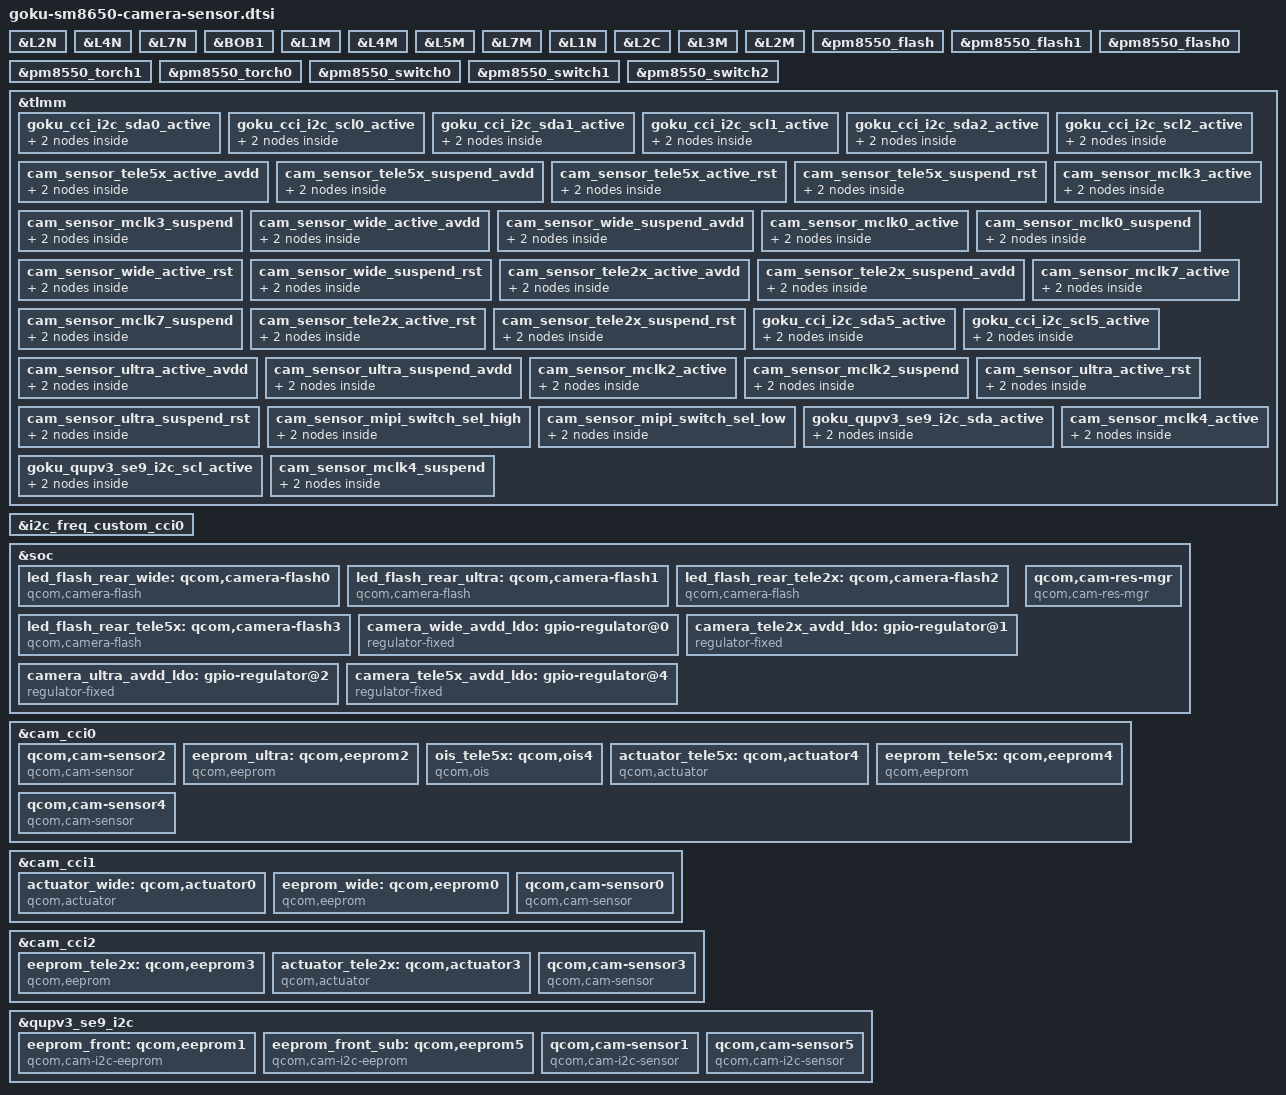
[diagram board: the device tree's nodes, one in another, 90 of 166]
#include <dt-bindings/msm-camera.h>

&L2N {
	regulator-min-microvolt = <1052000>;
	regulator-max-microvolt = <1052000>;
	qcom,init-voltage = <1052000>;
};

&L4N {
	regulator-min-microvolt = <2800000>;
	regulator-max-microvolt = <2800000>;
	qcom,init-voltage = <2800000>;
};

&L7N {
	regulator-min-microvolt = <2840000>;
	regulator-max-microvolt = <2840000>;
	qcom,init-voltage = <2840000>;
};

&BOB1{
	regulator-min-microvolt = <2704000>;
	regulator-max-microvolt = <3584000>;
	qcom,init-voltage = <3296000>;
};

&L1M {
	regulator-min-microvolt = <1160000>;
	regulator-max-microvolt = <1160000>;
	qcom,init-voltage = <1160000>;
};

&L4M {
	regulator-min-microvolt = <3144000>;
	regulator-max-microvolt = <3144000>;
	qcom,init-voltage = <3144000>;
};

&L5M {
	regulator-min-microvolt = <1800000>;
	regulator-max-microvolt = <1800000>;
	qcom,init-voltage = <1800000>;
};
&L7M {
	regulator-min-microvolt = <3112000>;
	regulator-max-microvolt = <3112000>;
	qcom,init-voltage = <3112000>;
};

&L1N {
	regulator-min-microvolt = <1104000>;
	regulator-max-microvolt = <1104000>;
	qcom,init-voltage = <1104000>;
};

&L2C {
	regulator-min-microvolt = <1216000>;
	regulator-max-microvolt = <1216000>;
	qcom,init-voltage = <1216000>;
};


&L3M{
	regulator-min-microvolt = <2824000>;
	regulator-max-microvolt = <2824000>;
	qcom,init-voltage = <2824000>;
};

&L2M {
	regulator-min-microvolt = <1232000>;
	regulator-max-microvolt = <1232000>;
	qcom,init-voltage = <1232000>;
};

&L5M {
	regulator-min-microvolt = <1800000>;
	regulator-max-microvolt = <1800000>;
	qcom,init-voltage = <1800000>;
};

&pm8550_flash {
	status = "ok";
};

&pm8550_flash1 {
	qcom,duration-ms = <300>;
	xiaomi,max-duration-ms = <300>;
	qcom,max-current-ma = <300>;
};

&pm8550_flash0 {
	qcom,duration-ms = <300>;
	xiaomi,max-duration-ms = <300>;
	qcom,max-current-ma = <300>;
};

&pm8550_torch1{
	qcom,max-current-ma = <300>;
	xiaomi,currents-with-time = <300 225>;
	xiaomi,time-for-currents = <5000 0xFFFFFFFF>;
};

&pm8550_torch0{
	qcom,max-current-ma = <300>;
	xiaomi,currents-with-time = <300 225>;
	xiaomi,time-for-currents = <5000 0xFFFFFFFF>;
};

&pm8550_switch0 {
	qcom,led-mask = <1>;
	qcom,symmetry-en;
};

&pm8550_switch1 {
	qcom,led-mask = <2>;
	qcom,symmetry-en;
};

&pm8550_switch2 {
	qcom,led-mask = <3>;
	qcom,symmetry-en;
};

&tlmm {
	goku_cci_i2c_sda0_active: goku_cci_i2c_sda0_active {
		mux {
			/* CLK, DATA */
			pins = "gpio113";
			function = "cci_i2c_sda0";
		};

		config {
			pins = "gpio113";
			bias-disable; /* NO PULL */
			drive-strength = <2>; /* 2 MA */
		};
	};

	goku_cci_i2c_scl0_active: goku_cci_i2c_scl0_active {
		mux {
			/* CLK, DATA */
			pins = "gpio114";
			function = "cci_i2c_scl0";
		};

		config {
			pins = "gpio114";
			bias-disable; /* NO PULL */
			drive-strength = <2>; /* 2 MA */
		};
	};

	goku_cci_i2c_sda1_active: goku_cci_i2c_sda1_active {
		mux {
			/* CLK, DATA */
			pins = "gpio115";
			function = "cci_i2c_sda1";
		};

		config {
			pins = "gpio115";
			bias-disable; /* NO PULL */
			drive-strength = <2>; /* 2 MA */
		};
	};

	goku_cci_i2c_scl1_active: goku_cci_i2c_scl1_active {
		mux {
			/* CLK, DATA */
			pins = "gpio116";
			function = "cci_i2c_scl1";
		};

		config {
			pins = "gpio116";
			bias-disable; /* NO PULL */
			drive-strength = <2>; /* 2 MA */
		};
	};

	goku_cci_i2c_sda2_active: goku_cci_i2c_sda2_active {
		mux {
			/* CLK, DATA */
			pins = "gpio117";
			function = "cci_i2c_sda2";
		};

		config {
			pins = "gpio117";
			bias-disable; /* NO PULL */
			drive-strength = <2>; /* 2 MA */
		};
	};

	goku_cci_i2c_scl2_active: goku_cci_i2c_scl2_active {
		mux {
			/* CLK, DATA */
			pins = "gpio118";
			function = "cci_i2c_scl2";
		};

		config {
			pins = "gpio118";
			bias-disable; /* NO PULL */
			drive-strength = <2>; /* 2 MA */
		};
	};

	// TELE5X
	cam_sensor_tele5x_active_avdd: cam_sensor_tele5x_active_avdd {
		mux {
			pins = "gpio82";
			function = "gpio";
		};

		config {
			pins = "gpio82";
			bias-disable; /* No PULL */
			drive-strength = <2>; /* 2 MA */
		};
	};

	cam_sensor_tele5x_suspend_avdd: cam_sensor_tele5x_suspend_avdd {
		mux {
			pins = "gpio82";
			function = "gpio";
		};

		config {
			pins = "gpio82";
			bias-disable; /* No PULL */
			drive-strength = <2>; /* 2 MA */
		};
	};

	cam_sensor_tele5x_active_rst: cam_sensor_tele5x_active_rst {
		mux {
			pins = "gpio110";
			function = "gpio";
		};

		config {
			pins = "gpio110";
			bias-disable; /* No PULL */
			drive-strength = <2>; /* 2 MA */
		};
	};

	cam_sensor_tele5x_suspend_rst: cam_sensor_tele5x_suspend_rst {
		mux {
			pins = "gpio110";
			function = "gpio";
		};

		config {
			pins = "gpio110";
			bias-pull-down; /* PULL DOWN */
			drive-strength = <2>; /* 2 MA */
			output-low;
		};
	};

	cam_sensor_mclk3_active: cam_sensor_mclk3_active {
		/* MCLK3 */
		mux {
			pins = "gpio103";
			function = "cam_mclk";
		};

		config {
			pins = "gpio103";
			bias-disable; /* No PULL */
			drive-strength = <4>; /* 4 MA */
		};
	};

	cam_sensor_mclk3_suspend: cam_sensor_mclk3_suspend {
		/* MCLK3 */
		mux {
			pins = "gpio103";
			function = "cam_mclk";
		};

		config {
			pins = "gpio103";
			bias-pull-down; /* PULL DOWN */
			drive-strength = <4>; /* 4 MA */
		};
	};


	cam_sensor_wide_active_avdd: cam_sensor_wide_active_avdd {
		mux {
			pins = "gpio178";
			function = "gpio";
		};

		config {
			pins = "gpio178";
			bias-disable; /* No PULL */
			drive-strength = <2>; /* 2 MA */
		};
	};

	cam_sensor_wide_suspend_avdd: cam_sensor_wide_suspend_avdd {
		mux {
			pins = "gpio178";
			function = "gpio";
		};

		config {
			pins = "gpio178";
			bias-pull-down; /* PULL DOWN */
			drive-strength = <2>; /* 2 MA */
			output-low;
		};
	};

	cam_sensor_mclk0_active: cam_sensor_mclk0_active {
		/* MCLK0 */
		mux {
			pins = "gpio100";
			function = "cam_mclk";
		};

		config {
			pins = "gpio100";
			bias-disable; /* No PULL */
			drive-strength = <4>; /* 4 MA */
		};
	};

	cam_sensor_mclk0_suspend: cam_sensor_mclk0_suspend {
		/* MCLK0 */
		mux {
			pins = "gpio100";
			function = "cam_mclk";
		};

		config {
			pins = "gpio100";
			bias-pull-down; /* PULL DOWN */
			drive-strength = <4>; /* 4 MA */
		};
	};

	cam_sensor_wide_active_rst: cam_sensor_wide_active_rst {
		mux {
			pins = "gpio108";
			function = "gpio";
		};

		config {
			pins = "gpio108";
			bias-disable; /* No PULL */
			drive-strength = <2>; /* 2 MA */
		};
	};

	cam_sensor_wide_suspend_rst: cam_sensor_wide_suspend_rst {
		mux {
			pins = "gpio108";
			function = "gpio";
		};

		config {
			pins = "gpio108";
			bias-pull-down; /* PULL DOWN */
			drive-strength = <2>; /* 2 MA */
			output-low;
		};
	};

	// TELE2X
	cam_sensor_tele2x_active_avdd: cam_sensor_tele2x_active_avdd {
		mux {
			pins = "gpio98";
			function = "gpio";
		};

		config {
			pins = "gpio98";
			bias-disable; /* No PULL */
			drive-strength = <2>; /* 2 MA */
		};
	};

	cam_sensor_tele2x_suspend_avdd: cam_sensor_tele2x_suspend_avdd {
		mux {
			pins = "gpio98";
			function = "gpio";
		};

		config {
			pins = "gpio98";
			bias-pull-down; /* PULL DOWN */
			drive-strength = <2>; /* 2 MA */
			output-low;
		};
	};

	cam_sensor_mclk7_active: cam_sensor_mclk7_active {
		/* MCLK7 */
		mux {
			pins = "gpio106";
			function = "cam_mclk";
		};

		config {
			pins = "gpio106";
			bias-disable; /* No PULL */
			drive-strength = <4>; /* 4 MA */
		};
	};

	cam_sensor_mclk7_suspend: cam_sensor_mclk7_suspend {
		/* MCLK7 */
		mux {
			pins = "gpio106";
			function = "cam_mclk";
		};

		config {
			pins = "gpio106";
			bias-pull-down; /* PULL DOWN */
			drive-strength = <4>; /* 4 MA */
		};
	};

	cam_sensor_tele2x_active_rst: cam_sensor_tele2x_active_rst {
		mux {
			pins = "gpio111";
			function = "gpio";
		};

		config {
			pins = "gpio111";
			bias-disable; /* No PULL */
			drive-strength = <2>; /* 2 MA */
		};
	};

	cam_sensor_tele2x_suspend_rst: cam_sensor_tele2x_suspend_rst {
		mux {
			pins = "gpio111";
			function = "gpio";
		};

		config {
			pins = "gpio111";
			bias-pull-down; /* PULL DOWN */
			drive-strength = <2>; /* 2 MA */
			output-low;
		};
	};

	goku_cci_i2c_sda5_active: goku_cci_i2c_sda5_active {
		mux {
			/* CLK, DATA */
			pins = "gpio119";
			function = "cci_i2c_sda5";
		};

		config {
			pins = "gpio119";
			bias-disable; /* NO PULL */
			drive-strength = <2>; /* 2 MA */
		};
	};

	goku_cci_i2c_scl5_active: goku_cci_i2c_scl5_active {
		mux {
			/* CLK, DATA */
			pins = "gpio120";
			function = "cci_i2c_scl5";
		};

		config {
			pins = "gpio120";
			bias-disable; /* NO PULL */
			drive-strength = <2>; /* 2 MA */
		};
	};

	// ULTRA avdd
	cam_sensor_ultra_active_avdd: cam_sensor_ultra_active_avdd {
		mux {
			pins = "gpio99";
			function = "gpio";
		};
		config {
			pins = "gpio99";
			bias-disable; /* No PULL */
			drive-strength = <2>; /* 2 MA */
		};
	};

	cam_sensor_ultra_suspend_avdd: cam_sensor_ultra_suspend_avdd {
		mux {
			pins = "gpio99";
			function = "gpio";
		};
		config {
			pins = "gpio99";
			bias-pull-down; /* PULL DOWN */
			drive-strength = <2>; /* 2 MA */
			output-low;
		};
	};

	//Ultra mclk
	cam_sensor_mclk2_active: cam_sensor_mclk2_active {
		/* MCLK1 */
		mux {
			pins = "gpio101";
			function = "cam_mclk";
		};
		config {
			pins = "gpio101";
			bias-disable; /* No PULL */
			drive-strength = <4>; /* 4 MA */
		};
	};

	cam_sensor_mclk2_suspend: cam_sensor_mclk2_suspend {
		/* MCLK1 */
		mux {
			pins = "gpio101";
			function = "cam_mclk";
		};
		config {
			pins = "gpio101";
			bias-pull-down; /* PULL DOWN */
			drive-strength = <4>; /* 4 MA */
		};
	};

	//Ultra RSN
	cam_sensor_ultra_active_rst: cam_sensor_ultra_active_rst {
		mux {
			pins = "gpio109";
			function = "gpio";
		};
		config {
			pins = "gpio109";
			bias-disable; /* No PULL */
			drive-strength = <2>; /* 2 MA */
		};
	};

	cam_sensor_ultra_suspend_rst: cam_sensor_ultra_suspend_rst {
		mux {
			pins = "gpio109";
			function = "gpio";
		};
		config {
			pins = "gpio109";
			bias-pull-down; /* PULL DOWN */
			drive-strength = <2>; /* 2 MA */
			output-low;
		};
	};

//FRONT


	cam_sensor_mipi_switch_sel_high: cam_sensor_mipi_switch_sel_high {
		/* MIPI SEL HIGH: FRONT SUB ACTIVE */

		mux {
			pins = "gpio91";
			function = "gpio";
		};

		config {
			pins = "gpio91";
			bias-disable; /* No PULL */
			drive-strength = <16>; /* 16 MA */
		};
	};

	cam_sensor_mipi_switch_sel_low: cam_sensor_mipi_switch_sel_low {
		/* MIPI SEL LOW: FRONT MAIN ACTIVE */
		mux {
			pins = "gpio91";
			function = "gpio";
		};

		config {
			pins = "gpio91";
			bias-pull-down; /* PULL DOWN */
			drive-strength = <16>; /* 16 MA */
			output-low;
		};
	};



	goku_qupv3_se9_i2c_sda_active: goku_qupv3_se9_i2c_sda_active {
		mux {
			pins = "gpio4";
			function = "qup2_se1_l0";
		};

		config {
			pins = "gpio4";
			drive-strength = <2>;
			bias-disable; /* NO PULL */
			qcom,apps;
		};
	};

	goku_qupv3_se9_i2c_scl_active: goku_qupv3_se9_i2c_scl_active {
		mux {
			pins = "gpio5";
			function = "qup2_se1_l1";
		};

		config {
			pins = "gpio5";
			drive-strength = <2>;
			bias-disable; /* NO PULL */
			qcom,apps;
		};
	};


	cam_sensor_mclk4_active: cam_sensor_mclk4_active {
		/* MCLK4 */
		mux {
			pins = "gpio104";
			function = "cam_aon_mclk4";
		};

		config {
			pins = "gpio104";
			bias-disable; /* No PULL */
			drive-strength = <4>; /* 4 MA */
		};
	};

	cam_sensor_mclk4_suspend: cam_sensor_mclk4_suspend {
		/* MCLK4 */
		mux {
			pins = "gpio104";
			function = "cam_aon_mclk4";
		};

		config {
			pins = "gpio104";
			bias-pull-down; /* PULL DOWN */
			drive-strength = <4>; /* 4 MA */
		};
	};

};

&i2c_freq_custom_cci0{
	hw-thigh = <16>;
	hw-tlow = <22>;
	hw-tsu-sto = <17>;
	hw-tsu-sta = <18>;
	hw-thd-dat = <16>;
	hw-thd-sta = <15>;
	hw-tbuf = <24>;
	hw-scl-stretch-en = <1>;
	hw-trdhld = <3>;
	hw-tsp = <3>;
	cci-clk-src = <37500000>;
	status = "ok";
};

&soc {
	led_flash_rear_wide: qcom,camera-flash0 {
		cell-index = <0>;
		compatible = "qcom,camera-flash";
		flash-source = <&pm8550_flash0 &pm8550_flash1>;
		torch-source = <&pm8550_torch0 &pm8550_torch1>;
		switch-source = <&pm8550_switch2>;
		status = "ok";
	};

	led_flash_rear_ultra: qcom,camera-flash1 {
		cell-index = <1>;
		compatible = "qcom,camera-flash";
		flash-source = <&pm8550_flash0 &pm8550_flash1>;
		torch-source = <&pm8550_torch0 &pm8550_torch1>;
		switch-source = <&pm8550_switch2>;
		status = "ok";
	};

	led_flash_rear_tele2x: qcom,camera-flash2 {
		cell-index = <2>;
		compatible = "qcom,camera-flash";
		flash-source = <&pm8550_flash0 &pm8550_flash1>;
		torch-source = <&pm8550_torch0 &pm8550_torch1>;
		switch-source = <&pm8550_switch2>;
		status = "ok";
	};

	led_flash_rear_tele5x: qcom,camera-flash3 {
		cell-index = <3>;
		compatible = "qcom,camera-flash";
		flash-source = <&pm8550_flash0 &pm8550_flash1>;
		torch-source = <&pm8550_torch0 &pm8550_torch1>;
		switch-source = <&pm8550_switch2>;
		status = "ok";
	};

	camera_wide_avdd_ldo: gpio-regulator@0 {
		compatible = "regulator-fixed";
		reg = <0x00 0x00>;
		regulator-name = "camera_wide_avdd_ldo";
		regulator-min-microvolt = <2800000>;
		regulator-max-microvolt = <2800000>;
		regulator-enable-ramp-delay = <100>;
		enable-active-high;
		gpio = <&tlmm 178 0>;
		pinctrl-names = "wide_avdd_active", "wide_avdd_suspend";
		pinctrl-0 = <&cam_sensor_wide_active_avdd
					 &cam_sensor_wide_suspend_avdd>;
	};

	camera_tele2x_avdd_ldo: gpio-regulator@1 {
		compatible = "regulator-fixed";
		reg = <0x01 0x00>;
		regulator-name = "camera_tele2x_avdd_ldo";
		regulator-min-microvolt = <2800000>;
		regulator-max-microvolt = <2800000>;
		regulator-enable-ramp-delay = <100>;
		enable-active-high;
		gpio = <&tlmm 98 0>;
		pinctrl-names = "tele2x_avdd_active", "tele2x_avdd_suspend";
		pinctrl-0 = <&cam_sensor_tele2x_active_avdd
					 &cam_sensor_tele2x_suspend_avdd>;
	};

	camera_ultra_avdd_ldo: gpio-regulator@2 {
		compatible = "regulator-fixed";
		reg = <0x02 0x00>;
		regulator-name = "camera_ultra_avdd_ldo";
		regulator-min-microvolt = <2800000>;
		regulator-max-microvolt = <2800000>;
		regulator-enable-ramp-delay = <100>;
		enable-active-high;
		gpio = <&tlmm 99 0>;
		pinctrl-names = "ultra_avdd_active", "ultra_avdd_suspend";
		pinctrl-0 = <&cam_sensor_ultra_active_avdd
					 &cam_sensor_ultra_suspend_avdd>;
	};

	camera_tele5x_avdd_ldo: gpio-regulator@4 {
		compatible = "regulator-fixed";
		reg = <0x04 0x00>;
		regulator-name = "camera_tele5x_avdd_ldo";
		regulator-min-microvolt = <2800000>;
		regulator-max-microvolt = <2800000>;
		regulator-enable-ramp-delay = <100>;
		enable-active-high;
		gpio = <&tlmm 82 0>;
		pinctrl-names = "tele5x_avdd_active", "tele5x_avdd_suspend";
		pinctrl-0 = <&cam_sensor_tele5x_active_avdd
					 &cam_sensor_tele5x_suspend_avdd>;
	};

	qcom,cam-res-mgr {
		compatible = "qcom,cam-res-mgr";
		gpios-shared-pinctrl = <404 411>;
		shared-pctrl-gpio-names = "cam_tele5x", "cam_tele5x";
		pinctrl-names ="cam_tele5x_active", "cam_tele5x_suspend";
		pinctrl-0 = <&cam_sensor_mclk3_active
				&cam_sensor_tele5x_active_rst>;
		pinctrl-1 = <&cam_sensor_mclk3_suspend
				&cam_sensor_tele5x_suspend_rst>;
		status = "ok";
	};
};


&cam_cci0 {
	pinctrl-0 = <&goku_cci_i2c_scl0_active &goku_cci_i2c_sda0_active>;
	pinctrl-2 = <&goku_cci_i2c_scl1_active &goku_cci_i2c_sda1_active>;

	// Ultra Sensor
	qcom,cam-sensor2 {
		cell-index = <2>;
		compatible = "qcom,cam-sensor";
		csiphy-sd-index = <1>;
		eeprom-src = <&eeprom_ultra>;
		led-flash-src = <&led_flash_rear_ultra>;
		sensor-position-roll = <90>;
		sensor-position-pitch = <0>;
		sensor-position-yaw = <180>;
		cam_vana-supply = <&camera_ultra_avdd_ldo>;
		cam_vdig-supply = <&L2C>;
		cam_vio-supply  = <&L5M>;
		cam_clk-supply  = <&cam_cc_titan_top_gdsc>;
		cam_bob2-supply = <&BOB2>;
		regulator-names = "cam_vana", "cam_vio", "cam_vdig",
			"cam_clk", "cam_bob2";
		rgltr-cntrl-support;
		rgltr-min-voltage = <2800000 1800000 1216000 0 2704000>;
		rgltr-max-voltage = <2800000 1800000 1216000 0 3296000>;
		rgltr-load-current = <150000 150000 150000 0 2000000>;
		//use-shared-clk;
		gpio-no-mux = <0>;
		pinctrl-names = "cam_default", "cam_suspend";
		pinctrl-0 = <&cam_sensor_mclk2_active
					&cam_sensor_ultra_active_rst>;
		pinctrl-1 = <&cam_sensor_mclk2_suspend
					&cam_sensor_ultra_suspend_rst>;
		gpios = <&tlmm 101 0>, <&tlmm 109 0>;
		gpio-reset = <1>;
		gpio-req-tbl-num = <0 1>;
		gpio-req-tbl-flags = <1 0>;
		gpio-req-tbl-label = "CAMIF_MCLK1", "CAM_RESET1";
		cci-master = <CCI_MASTER_1>;
		clocks = <&camcc CAM_CC_MCLK1_CLK>;
		clock-names = "cam_clk";
		clock-cntl-level = "nominal";
		clock-rates = <19200000>;
		status = "ok";
	};

	eeprom_ultra: qcom,eeprom2 {
		cell-index = <2>;
		compatible = "qcom,eeprom";
		cam_vana-supply = <&camera_ultra_avdd_ldo>;
		cam_vdig-supply = <&L2C>;
		cam_vio-supply  = <&L5M>;
		cam_clk-supply  = <&cam_cc_titan_top_gdsc>;
		cam_bob2-supply = <&BOB2>;
		regulator-names = "cam_vana", "cam_vio", "cam_vdig",
			"cam_clk", "cam_bob2";
		rgltr-cntrl-support;
		rgltr-min-voltage = <2800000 1800000 1216000 0 2704000>;
		rgltr-max-voltage = <2800000 1800000 1216000 0 3296000>;
		rgltr-load-current = <150000 150000 150000 0 2000000>;
		pinctrl-names = "cam_default", "cam_suspend";
		pinctrl-0 = <&cam_sensor_mclk2_active
					&cam_sensor_ultra_active_rst>;
		pinctrl-1 = <&cam_sensor_mclk2_suspend
					&cam_sensor_ultra_suspend_rst>;
		gpios = <&tlmm 101 0>, <&tlmm 109 0>;
		gpio-reset = <1>;
		gpio-req-tbl-num = <0 1>;
		gpio-req-tbl-flags = <1 0>;
		gpio-req-tbl-label = "CAMIF_MCLK1", "CAM_RESET1";
		cci-master = <CCI_MASTER_1>;
		clocks = <&camcc CAM_CC_MCLK1_CLK>;
		clock-names = "cam_clk";
		clock-cntl-level = "nominal";
		clock-rates = <19200000>;
		status = "ok";
	};


	// Tele5x OIS
	ois_tele5x: qcom,ois4 {
		cell-index = <4>;
		compatible = "qcom,ois";
		cam_vana-supply = <&camera_tele5x_avdd_ldo>;
		cam_vio-supply = <&L5M>;
		cam_vdig-supply = <&L2N>;
		cam_clk-supply = <&cam_cc_titan_top_gdsc>;
		cam_bob2-supply = <&BOB2>;
		cam_bob-supply = <&BOB1>;
		cam_v_custom1-supply = <&L4N>;/*OIS AVDD*/
		cam_vaf-supply = <&L7N>;
		regulator-names = "cam_vana", "cam_vio", "cam_vdig",
			"cam_clk", "cam_bob2", "cam_bob", "cam_v_custom1", "cam_vaf";
		rgltr-cntrl-support;
		rgltr-min-voltage = <2800000 1800000 1052000 0 2704000 2704000 2800000 2840000>;
		rgltr-max-voltage = <2800000 1800000 1052000 0 3296000 3584000 2800000 2840000>;
		rgltr-load-current = <150000 150000 150000 0 2000000 2000000 103000 103000>;
		gpio-no-mux = <0>;
		use-shared-clk;
		gpios = <&tlmm 103 0>, <&tlmm 110 0>;
		gpio-reset = <1>;
		gpio-req-tbl-num = <0 1>;
		gpio-req-tbl-flags = <1 0>;
		gpio-req-tbl-label = "CAMIF_MCLK3", "CAM_RESET_TELE5X";
		cci-master = <CCI_MASTER_0>;
		clocks = <&camcc CAM_CC_MCLK3_CLK>;
		clock-names = "cam_clk";
		clock-cntl-level = "nominal";
		clock-rates = <19200000>;
		status = "ok";
	};

	// Tele5x Actuator
	actuator_tele5x: qcom,actuator4 {
		cell-index = <4>;
		compatible = "qcom,actuator";
		cci-master = <CCI_MASTER_0>;
		cam_vaf-supply = <&L7N>;
		cam_vio-supply = <&L5M>;
		cam_v_custom1-supply = <&L4N>;
		cam_bob-supply = <&BOB1>;
		regulator-names = "cam_vaf", "cam_vio", "cam_v_custom1", "cam_bob";
		rgltr-cntrl-support;
		rgltr-min-voltage = <2840000 1800000 2800000 2704000>;
		rgltr-max-voltage = <2840000 1800000 2800000 3584000>;
		rgltr-load-current = <103000 150000 103000 2000000>;
	};

	eeprom_tele5x: qcom,eeprom4 {
		cell-index = <4>;
		compatible = "qcom,eeprom";
		cam_vana-supply = <&camera_tele5x_avdd_ldo>;
		cam_vio-supply = <&L5M>;
		cam_vdig-supply = <&L2N>;
		cam_clk-supply = <&cam_cc_titan_top_gdsc>;
		cam_bob2-supply = <&BOB2>;
		cam_bob-supply = <&BOB1>;
		cam_v_custom1-supply = <&L4N>;/*OIS AVDD*/
		cam_vaf-supply = <&L7N>;
		regulator-names = "cam_vana", "cam_vio", "cam_vdig",
			"cam_clk", "cam_bob2", "cam_bob", "cam_v_custom1", "cam_vaf";
		rgltr-cntrl-support;
		rgltr-min-voltage = <2800000 1800000 1052000 0 2704000 2704000 2800000 2840000>;
		rgltr-max-voltage = <2800000 1800000 1052000 0 3296000 3584000 2800000 2840000>;
		rgltr-load-current = <150000 150000 150000 0 2000000 2000000 103000 103000>;
		gpio-no-mux = <0>;
		use-shared-clk;
		gpios = <&tlmm 103 0>, <&tlmm 110 0>;
		gpio-reset = <1>;
		gpio-req-tbl-num = <0 1>;
		gpio-req-tbl-flags = <1 0>;
		gpio-req-tbl-label = "CAMIF_MCLK3", "CAM_RESET_TELE5X";
		cci-master = <CCI_MASTER_0>;
		clocks = <&camcc CAM_CC_MCLK3_CLK>;
		clock-names = "cam_clk";
		clock-cntl-level = "nominal";
		clock-rates = <19200000>;
		status = "ok";
	};

	// Tele5x Sensor
	qcom,cam-sensor4 {
		cell-index = <4>;
		compatible = "qcom,cam-sensor";
		csiphy-sd-index = <5>;
		eeprom-src = <&eeprom_tele5x>;
		ois-src = <&ois_tele5x>;
		actuator-src = <&actuator_tele5x>;
		led-flash-src = <&led_flash_rear_tele5x>;
		sensor-position-roll = <90>;
		sensor-position-pitch = <0>;
		sensor-position-yaw = <180>;
		cam_vana-supply = <&camera_tele5x_avdd_ldo>;
		cam_vio-supply = <&L5M>;
		cam_vdig-supply = <&L2N>;
		cam_clk-supply = <&cam_cc_titan_top_gdsc>;
		cam_bob2-supply = <&BOB2>;
		cam_bob-supply = <&BOB1>;
		cam_vaf-supply = <&L7N>;
		cam_v_custom1-supply = <&L4N>;/*OIS AVDD*/
		regulator-names = "cam_vana", "cam_vio", "cam_vdig",
			"cam_clk", "cam_bob2", "cam_bob", "cam_v_custom1", "cam_vaf";
		rgltr-cntrl-support;
		rgltr-min-voltage = <2800000 1800000 1052000 0 2704000 2704000 2800000 2840000>;
		rgltr-max-voltage = <2800000 1800000 1052000 0 3296000 3584000 2800000 2840000>;
		rgltr-load-current = <150000 150000 150000 0 2000000 2000000 103000 103000>;
		gpio-no-mux = <0>;
		use-shared-clk;
		gpios = <&tlmm 103 0>, <&tlmm 110 0>;
		gpio-reset = <1>;
		gpio-req-tbl-num = <0 1>;
		gpio-req-tbl-flags = <1 0>;
		gpio-req-tbl-label = "CAMIF_MCLK3", "CAM_RESET_TELE5X";
		cci-master = <CCI_MASTER_0>;
		clocks = <&camcc CAM_CC_MCLK3_CLK>;
		clock-names = "cam_clk";
		clock-cntl-level = "nominal";
		clock-rates = <19200000>;
		status = "ok";
	};
};

&cam_cci1 {
	pinctrl-0 = <&goku_cci_i2c_scl2_active &goku_cci_i2c_sda2_active>;

    //WIDE SubDev
    actuator_wide: qcom,actuator0 {
		cell-index = <0>;
		compatible = "qcom,actuator";
		cci-master = <CCI_MASTER_0>;
		// cam_bob-supply = <&BOB1>;
		cam_vaf-supply = <&L4M>;
		cam_vio-supply = <&L5M>;
		regulator-names = "cam_vaf", "cam_vio";
		rgltr-cntrl-support;
		rgltr-min-voltage = <3144000 1800000>;
		rgltr-max-voltage = <3144000 1800000>;
		rgltr-load-current = <103000 20000>;
	};

	eeprom_wide: qcom,eeprom0 {
		cell-index = <0>;
		compatible = "qcom,eeprom";
		cam_vana-supply = <&camera_wide_avdd_ldo>;
		cam_vio-supply = <&L5M>;
		cam_vdig-supply = <&L1M>;
		cam_clk-supply = <&cam_cc_titan_top_gdsc>;
		cam_bob2-supply = <&BOB2>;
		cam_bob-supply = <&BOB1>;
		regulator-names = "cam_vana", "cam_vio", "cam_vdig",
			"cam_clk", "cam_bob2", "cam_bob";
		rgltr-cntrl-support;
		rgltr-min-voltage = <2800000 1800000 1160000 0 2704000 2704000>;
		rgltr-max-voltage = <2800000 1800000 1160000 0 3296000 3584000>;
		rgltr-load-current = <150000 150000 150000 0 2000000 2000000>;

		gpio-no-mux = <0>;
		pinctrl-names = "cam_default", "cam_suspend";
		pinctrl-0 = <&cam_sensor_mclk0_active
			&cam_sensor_wide_active_rst>;
		pinctrl-1 = <&cam_sensor_mclk0_suspend
			&cam_sensor_wide_suspend_rst>;
		//use-shared-clk;
		gpios = <&tlmm 100 0>, <&tlmm 108 0>;
		gpio-reset = <1>;
		gpio-req-tbl-num = <0 1>;
		gpio-req-tbl-flags = <1 0>;
		gpio-req-tbl-label = "CAMIF_MCLK0", "CAM_RESET_WIDE";
		cci-master = <CCI_MASTER_0>;
		clocks = <&camcc CAM_CC_MCLK0_CLK>;
		clock-names = "cam_clk";
		clock-cntl-level = "nominal";
		clock-rates = <19200000>;
		status = "ok";
	};

	// Wide Sensor
	qcom,cam-sensor0 {
		cell-index = <0>;
		compatible = "qcom,cam-sensor";
		csiphy-sd-index = <2>;
		led-flash-src = <&led_flash_rear_wide>;
		eeprom-src = <&eeprom_wide>;
		actuator-src = <&actuator_wide>;
		sensor-position-roll = <90>;
		sensor-position-pitch = <0>;
		sensor-position-yaw = <180>;
		cam_vana-supply = <&camera_wide_avdd_ldo>;
		cam_vio-supply = <&L5M>;
		cam_vdig-supply = <&L1M>;
		cam_clk-supply = <&cam_cc_titan_top_gdsc>;
		cam_bob2-supply = <&BOB2>;
		cam_bob-supply = <&BOB1>;
		regulator-names = "cam_vana", "cam_vio", "cam_vdig",
			"cam_clk", "cam_bob2", "cam_bob";
		rgltr-cntrl-support;
		rgltr-min-voltage = <2800000 1800000 1160000 0 2704000 2704000>;
		rgltr-max-voltage = <2800000 1800000 1160000 0 3296000 3584000>;
		rgltr-load-current = <150000 150000 150000 0 2000000 2000000>;
		gpio-no-mux = <0>;
		pinctrl-names = "cam_default", "cam_suspend";
		pinctrl-0 = <&cam_sensor_mclk0_active
			&cam_sensor_wide_active_rst>;
		pinctrl-1 = <&cam_sensor_mclk0_suspend
			&cam_sensor_wide_suspend_rst>;
		//use-shared-clk;
		gpios = <&tlmm 100 0>, <&tlmm 108 0>;
		gpio-reset = <1>;
		gpio-req-tbl-num = <0 1>;
		gpio-req-tbl-flags = <1 0>;
		gpio-req-tbl-label = "CAMIF_MCLK0", "CAM_RESET_WIDE";
		cci-master = <CCI_MASTER_0>;
		clocks = <&camcc CAM_CC_MCLK0_CLK>;
		clock-names = "cam_clk";
		clock-cntl-level = "nominal";
		clock-rates = <19200000>;
		status = "ok";
	};
};

&cam_cci2 {
	pinctrl-2 = <&goku_cci_i2c_sda5_active &goku_cci_i2c_scl5_active>;

	eeprom_tele2x: qcom,eeprom3 {
		cell-index = <3>;
		compatible = "qcom,eeprom";
		cam_vana-supply = <&camera_tele2x_avdd_ldo>;
		cam_vio-supply = <&L5M>;
		cam_vdig-supply = <&L1N>;
		cam_bob2-supply = <&BOB2>;
		cam_bob-supply = <&BOB1>;
		cam_clk-supply = <&cam_cc_titan_top_gdsc>;
		regulator-names = "cam_vana", "cam_vio", "cam_vdig",
					"cam_clk", "cam_bob2", "cam_bob";
		rgltr-cntrl-support;
		rgltr-min-voltage = <2800000 1800000 1104000 0 2704000 2704000>;
		rgltr-max-voltage = <2800000 1800000 1104000 0 3296000 3584000>;
		rgltr-load-current = <150000 150000 150000 0 2000000 2000000>;
		gpio-no-mux = <0>;
		pinctrl-names = "cam_default", "cam_suspend";
		pinctrl-0 = <&cam_sensor_mclk7_active
			&cam_sensor_tele2x_active_rst>;
		pinctrl-1 = <&cam_sensor_mclk7_suspend
			&cam_sensor_tele2x_suspend_rst>;
		gpios = <&tlmm 106 0>, <&tlmm 111 0>;
		gpio-reset = <1>;
		gpio-req-tbl-num = <0 1>;
		gpio-req-tbl-flags = <1 0>;
		gpio-req-tbl-label = "CAMIF_MCLK7", "CAM_RESET_TELE2X";
		cci-master = <CCI_MASTER_1>;
		clocks = <&camcc CAM_CC_MCLK7_CLK>;
		clock-names = "cam_clk";
		clock-cntl-level = "nominal";
		clock-rates = <19200000>;
		status = "ok";
	};

	// Tele2x Actuator
	actuator_tele2x: qcom,actuator3 {
		cell-index = <3>;
		compatible = "qcom,actuator";
		cci-master = <CCI_MASTER_1>;
		cam_vaf-supply = <&L7M>;
		cam_vio-supply = <&L5M>;
		regulator-names = "cam_vaf", "cam_vio";
		rgltr-cntrl-support;
		rgltr-min-voltage = <3112000 1800000>;
		rgltr-max-voltage = <3112000 1800000>;
		rgltr-load-current = <103000 150000>;
    };

	// Tele2x Sensor
	qcom,cam-sensor3 {
		cell-index = <3>;
		compatible = "qcom,cam-sensor";
		csiphy-sd-index = <3>;
		actuator-src = <&actuator_tele2x>;
		eeprom-src = <&eeprom_tele2x>;
		led-flash-src = <&led_flash_rear_tele2x>;
		sensor-position-roll = <90>;
		sensor-position-pitch = <0>;
		sensor-position-yaw = <180>;
		cam_vana-supply = <&camera_tele2x_avdd_ldo>;
		cam_vio-supply = <&L5M>;
		cam_vdig-supply = <&L1N>;
		cam_bob2-supply = <&BOB2>;
		cam_bob-supply = <&BOB1>;
		cam_clk-supply = <&cam_cc_titan_top_gdsc>;
		regulator-names = "cam_vana", "cam_vio", "cam_vdig",
					"cam_clk", "cam_bob2", "cam_bob";
		rgltr-cntrl-support;
		rgltr-min-voltage = <2800000 1800000 1104000 0 2704000 2704000>;
		rgltr-max-voltage = <2800000 1800000 1104000 0 3296000 3584000>;
		rgltr-load-current = <150000 150000 150000 0 2000000 2000000>;
		gpio-no-mux = <0>;
		pinctrl-names = "cam_default", "cam_suspend";
		pinctrl-0 = <&cam_sensor_mclk7_active
			&cam_sensor_tele2x_active_rst>;
		pinctrl-1 = <&cam_sensor_mclk7_suspend
			&cam_sensor_tele2x_suspend_rst>;
		gpios = <&tlmm 106 0>, <&tlmm 111 0>;
		gpio-reset = <1>;
		gpio-req-tbl-num = <0 1>;
		gpio-req-tbl-flags = <1 0>;
		gpio-req-tbl-label = "CAMIF_MCLK7", "CAM_RESET_TELE2X";
		cci-master = <CCI_MASTER_1>;
		clocks = <&camcc CAM_CC_MCLK7_CLK>;
		clock-names = "cam_clk";
		clock-cntl-level = "nominal";
		clock-rates = <19200000>;
		status = "ok";
	};
};

&qupv3_se9_i2c {
	status = "ok";
	qcom,clk-freq-out = <1000000>;
	qcom,pm-ctrl-client;
	pinctrl-0 = <&goku_qupv3_se9_i2c_sda_active>, <&goku_qupv3_se9_i2c_scl_active>;

	// main front eeprom
	eeprom_front: qcom,eeprom1 {
		cell-index = <1>;
		reg = <0x51>;
		compatible = "qcom,cam-i2c-eeprom";
		cam_vana-supply = <&L3M>;
		cam_vio-supply = <&L5M>;
		cam_vdig-supply = <&L2M>;
		cam_clk-supply = <&cam_cc_titan_top_gdsc>;
		cam_bob-supply = <&BOB1>;
		regulator-names = "cam_vana", "cam_vio",
			"cam_vdig", "cam_clk","cam_bob1";
		rgltr-cntrl-support;
		// aon-camera-id = <AON_CAM1>;
		rgltr-min-voltage = <2824000 1800000 1232000 0 2704000>;
		rgltr-max-voltage = <2824000 1800000 1232000 0 3584000>;
		rgltr-load-current = <43500 150000 150000 0 2000000>;
                gpio-no-mux = <0>;
		pinctrl-names = "cam_default", "cam_suspend";
		pinctrl-0 = <&cam_sensor_mipi_switch_sel_low>;
		pinctrl-1 = <&cam_sensor_mipi_switch_sel_high>;
		gpios = <&tlmm 91 0>;
		gpio-custom1 = <0>;
		gpio-req-tbl-num = <0>;
		gpio-req-tbl-flags = <0>;
		gpio-req-tbl-label = "CAM_MIPISEL0";
		status = "ok";
	};

	//sub front eeprom
	eeprom_front_sub: qcom,eeprom5 {
		cell-index = <5>;
		reg = <0x55>;
		compatible = "qcom,cam-i2c-eeprom";
		cam_vana-supply = <&L3M>;
		cam_vio-supply = <&L5M>;
		cam_vdig-supply = <&L2M>;
		cam_clk-supply = <&cam_cc_titan_top_gdsc>;
		cam_bob-supply = <&BOB1>;
		regulator-names = "cam_vana", "cam_vio",
			"cam_vdig", "cam_clk","cam_bob1";
		rgltr-cntrl-support;
		// aon-camera-id = <AON_CAM1>;
		rgltr-min-voltage = <2824000 1800000 1232000 0 2704000>;
		rgltr-max-voltage = <2824000 1800000 1232000 0 3584000>;
		rgltr-load-current = <43500 150000 150000 0 2000000>;
                gpio-no-mux = <0>;
		pinctrl-names = "cam_default", "cam_suspend";
		pinctrl-0 = <&cam_sensor_mipi_switch_sel_low>;
		pinctrl-1 = <&cam_sensor_mipi_switch_sel_high>;
		gpios = <&tlmm 91 0>;
		gpio-custom1 = <0>;
		gpio-req-tbl-num = <0>;
		gpio-req-tbl-flags = <0>;
		gpio-req-tbl-label = "CAM_MIPISEL0";
		status = "ok";
	};


	// Front Sensor
	qcom,cam-sensor1 {
		cell-index = <1>;
		reg = <0x10>;
		compatible = "qcom,cam-i2c-sensor";
		csiphy-sd-index = <4>;
		eeprom-src = <&eeprom_front>;
		sensor-position-roll = <270>;
		sensor-position-pitch = <0>;
		sensor-position-yaw = <0>;
		cam_vana-supply = <&L3M>;
		cam_vio-supply = <&L5M>;
		cam_vdig-supply = <&L2M>;
		cam_clk-supply = <&cam_cc_titan_top_gdsc>;
		cam_bob-supply = <&BOB1>;
		regulator-names = "cam_vana", "cam_vio",
			"cam_vdig", "cam_clk","cam_bob1";
		rgltr-cntrl-support;
		aon-camera-id = <AON_CAM1>;
		rgltr-min-voltage = <2824000 1800000 1232000 0 2704000>;
		rgltr-max-voltage = <2824000 1800000 1232000 0 3584000>;
		rgltr-load-current = <43500 150000 150000 0 2000000>;
		gpio-no-mux = <0>;
		pinctrl-names = "cam_default", "cam_suspend";
		pinctrl-0 = <&cam_sensor_mclk4_active
			&cam_sensor_active_rst4
			&cam_sensor_mipi_switch_sel_low>;
		pinctrl-1 = <&cam_sensor_mclk4_suspend
			&cam_sensor_suspend_rst4
			&cam_sensor_mipi_switch_sel_high>;
		gpios = <&tlmm 104 0>, <&tlmm 7 0>, <&tlmm 91 0>;
		gpio-reset = <1>;
		gpio-custom1 = <2>;
		gpio-req-tbl-num = <0 1 2>;
		gpio-req-tbl-flags = <1 0 0>;
		gpio-req-tbl-label = "CAMIF_MCLK4", "CAM_RESET4", "CAM_MIPISEL0";
		clocks = <&camcc CAM_CC_MCLK4_CLK>;
		clock-names = "cam_clk";
		clock-cntl-level = "nominal";
		clock-rates = <19200000>;
		status = "ok";
	};

	// sub front Sensor
	qcom,cam-sensor5 {
		cell-index = <5>;
		reg = <0x11>;
		compatible = "qcom,cam-i2c-sensor";
		csiphy-sd-index = <4>;
		eeprom-src = <&eeprom_front_sub>;
		sensor-position-roll = <270>;
		sensor-position-pitch = <0>;
		sensor-position-yaw = <0>;
		cam_vana-supply = <&L3M>;
		cam_vio-supply = <&L5M>;
		cam_vdig-supply = <&L2M>;
		cam_clk-supply = <&cam_cc_titan_top_gdsc>;
		cam_bob-supply = <&BOB1>;
		regulator-names = "cam_vana", "cam_vio",
			"cam_vdig", "cam_clk","cam_bob1";
		rgltr-cntrl-support;
		aon-camera-id = <AON_CAM1>;
		rgltr-min-voltage = <2824000 1800000 1232000 0 2704000>;
		rgltr-max-voltage = <2824000 1800000 1232000 0 3584000>;
		rgltr-load-current = <43500 150000 150000 0 2000000>;
		gpio-no-mux = <0>;
		pinctrl-names = "cam_default", "cam_suspend";
		pinctrl-0 = <&cam_sensor_mclk4_active
			&cam_sensor_active_rst4
			&cam_sensor_mipi_switch_sel_low>;
		pinctrl-1 = <&cam_sensor_mclk4_suspend
			&cam_sensor_suspend_rst4
			&cam_sensor_mipi_switch_sel_high>;
		gpios = <&tlmm 104 0>, <&tlmm 7 0>, <&tlmm 91 0>;
		gpio-reset = <1>;
		gpio-custom1 = <2>;
		gpio-req-tbl-num = <0 1 2>;
		gpio-req-tbl-flags = <1 0 0>;
		gpio-req-tbl-label = "CAMIF_MCLK4", "CAM_RESET4", "CAM_MIPISEL0";
		clocks = <&camcc CAM_CC_MCLK4_CLK>;
		clock-names = "cam_clk";
		clock-cntl-level = "nominal";
		clock-rates = <19200000>;
		status = "ok";
	};
};
